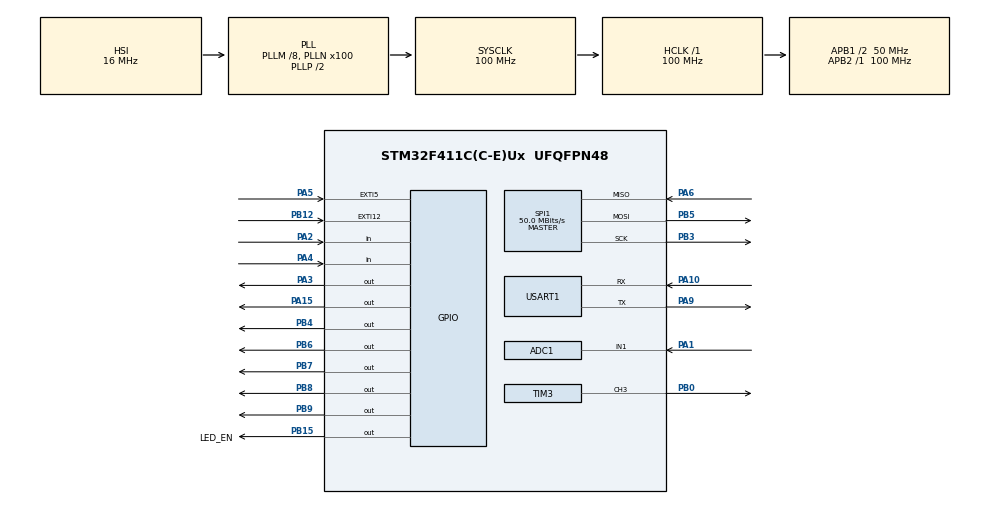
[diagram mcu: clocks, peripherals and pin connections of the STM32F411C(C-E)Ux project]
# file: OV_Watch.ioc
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ADC1.Channel-0\#ChannelRegularConversion=ADC_CHANNEL_1
ADC1.NbrOfConversionFlag=1
ADC1.Rank-0\#ChannelRegularConversion=1
ADC1.SamplingTime-0\#ChannelRegularConversion=ADC_SAMPLETIME_3CYCLES
ADC1.master=1
Dma.Request0=SPI1_TX
Dma.SPI1_TX.0.Direction=DMA_MEMORY_TO_PERIPH
Dma.SPI1_TX.0.FIFOMode=DMA_FIFOMODE_DISABLE
Dma.SPI1_TX.0.Instance=DMA2_Stream2
Dma.SPI1_TX.0.MemDataAlignment=DMA_MDATAALIGN_BYTE
Dma.SPI1_TX.0.MemInc=DMA_MINC_ENABLE
Dma.SPI1_TX.0.Mode=DMA_NORMAL
Dma.SPI1_TX.0.PeriphDataAlignment=DMA_PDATAALIGN_BYTE
Dma.SPI1_TX.0.PeriphInc=DMA_PINC_DISABLE
Dma.SPI1_TX.0.Priority=DMA_PRIORITY_HIGH
Mcu.Family=STM32F4
Mcu.Name=STM32F411C(C-E)Ux
Mcu.Package=UFQFPN48
NVIC.DMA2_Stream2_IRQn=true\:0\:0\:false\:false\:true\:false\:true\:true
NVIC.EXTI15_10_IRQn=true\:0\:0\:false\:false\:true\:true\:true\:true
NVIC.EXTI9_5_IRQn=true\:0\:0\:false\:false\:true\:true\:true\:true
NVIC.PriorityGroup=NVIC_PRIORITYGROUP_4
NVIC.SPI1_IRQn=true\:0\:0\:false\:false\:true\:true\:true\:true
NVIC.TIM1_UP_TIM10_IRQn=true\:0\:0\:false\:false\:true\:true\:true\:true
NVIC.USART1_IRQn=true\:0\:0\:false\:false\:true\:true\:true\:true
PA1.Signal=SharedAnalog_PA1
PA10.Mode=Asynchronous
PA10.Signal=USART1_RX
PA13.Mode=Serial_Wire
PA13.Signal=SYS_JTMS-SWDIO
PA14.Mode=Serial_Wire
PA14.Signal=SYS_JTCK-SWCLK
PA15.GPIO_PuPd=GPIO_PULLUP
PA15.PinState=GPIO_PIN_SET
PA15.Signal=GPIO_Output
PA2.GPIO_PuPd=GPIO_PULLUP
PA2.Signal=GPIO_Input
PA3.PinState=GPIO_PIN_SET
PA3.Signal=GPIO_Output
PA4.GPIO_PuPd=GPIO_PULLDOWN
PA4.Signal=GPIO_Input
PA5.GPIO_ModeDefaultEXTI=GPIO_MODE_IT_FALLING
PA5.GPIO_PuPd=GPIO_PULLUP
PA5.Signal=GPXTI5
PA6.Mode=Full_Duplex_Master
PA6.Signal=SPI1_MISO
PA9.Mode=Asynchronous
PA9.Signal=USART1_TX
PB0.Signal=S_TIM3_CH3
PB12.GPIO_ModeDefaultEXTI=GPIO_MODE_IT_FALLING
PB12.GPIO_PuPd=GPIO_PULLUP
PB12.Signal=GPXTI12
PB15.GPIO_Label=LED_EN
PB15.GPIO_PuPd=GPIO_NOPULL
PB15.PinState=GPIO_PIN_SET
PB15.Signal=GPIO_Output
PB3.Mode=Full_Duplex_Master
PB3.Signal=SPI1_SCK
PB4.GPIO_ModeDefaultOutputPP=GPIO_MODE_OUTPUT_OD
PB4.GPIO_PuPd=GPIO_PULLUP
PB4.GPIO_Speed=GPIO_SPEED_FREQ_HIGH
PB4.PinState=GPIO_PIN_SET
PB4.Signal=GPIO_Output
PB5.Mode=Full_Duplex_Master
PB5.Signal=SPI1_MOSI
PB6.GPIO_ModeDefaultOutputPP=GPIO_MODE_OUTPUT_OD
PB6.GPIO_PuPd=GPIO_PULLUP
PB6.GPIO_Speed=GPIO_SPEED_FREQ_HIGH
PB6.PinState=GPIO_PIN_SET
PB6.Signal=GPIO_Output
PB7.GPIO_PuPd=GPIO_PULLUP
PB7.PinState=GPIO_PIN_SET
PB7.Signal=GPIO_Output
PB8.GPIO_PuPd=GPIO_PULLUP
PB8.GPIO_Speed=GPIO_SPEED_FREQ_HIGH
PB8.PinState=GPIO_PIN_SET
PB8.Signal=GPIO_Output
PB9.GPIO_PuPd=GPIO_NOPULL
PB9.GPIO_Speed=GPIO_SPEED_FREQ_HIGH
PB9.PinState=GPIO_PIN_SET
PB9.Signal=GPIO_Output
PC14-OSC32_IN.Mode=LSE-External-Oscillator
PC14-OSC32_IN.Signal=RCC_OSC32_IN
PC15-OSC32_OUT.Mode=LSE-External-Oscillator
PC15-OSC32_OUT.Signal=RCC_OSC32_OUT
ProjectManager.HeapSize=0x200
ProjectManager.StackSize=0x400
ProjectManager.TargetToolchain=CMake
RCC.48MHZClocksFreq_Value=50000000
RCC.AHBFreq_Value=100000000
RCC.APB1CLKDivider=RCC_HCLK_DIV2
RCC.APB1Freq_Value=50000000
RCC.APB1TimFreq_Value=100000000
RCC.APB2Freq_Value=100000000
RCC.APB2TimFreq_Value=100000000
RCC.CortexFreq_Value=100000000
RCC.HCLKFreq_Value=100000000
RCC.HSE_VALUE=25000000
RCC.HSI_VALUE=16000000
RCC.PLLM=8
RCC.PLLN=100
RCC.SYSCLKFreq_VALUE=100000000
RCC.SYSCLKSource=RCC_SYSCLKSOURCE_PLLCLK
RCC.VCOOutputFreq_Value=200000000
RTC.Date=15
RTC.Hours=12
RTC.Month=RTC_MONTH_JULY
RTC.Year=26
SH.S_TIM3_CH3.0=TIM3_CH3,PWM Generation3 CH3
SH.SharedAnalog_PA1.0=GPIO_Analog
SH.SharedAnalog_PA1.1=ADC1_IN1,IN1
SPI1.BaudRatePrescaler=SPI_BAUDRATEPRESCALER_2
SPI1.CalculateBaudRate=50.0 MBits/s
SPI1.DataSize=SPI_DATASIZE_8BIT
SPI1.Direction=SPI_DIRECTION_2LINES
SPI1.Mode=SPI_MODE_MASTER
SPI1.VirtualType=VM_MASTER
TIM10.Prescaler=99
TIM3.Channel-PWM\ Generation3\ CH3=TIM_CHANNEL_3
TIM3.CounterMode=TIM_COUNTERMODE_UP
TIM3.Period=999
TIM3.Prescaler=9
TIM3.Pulse-PWM\ Generation3\ CH3=800
USART1.VirtualMode=VM_ASYNC
VP_RTC_VS_RTC_Activate.Mode=RTC_Enabled
VP_RTC_VS_RTC_Calendar.Mode=RTC_Calendar
VP_TIM10_VS_ClockSourceINT.Mode=Enable_Timer
board=custom

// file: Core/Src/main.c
/* USER CODE BEGIN Header */
/**
  ******************************************************************************
  * @file           : main.c
  * @brief          : Main program body
  ******************************************************************************
  * @attention
  *
  * Copyright (c) 2026 STMicroelectronics.
  * All rights reserved.
  *
  * This software is licensed under terms that can be found in the LICENSE file
  * in the root directory of this software component.
  * If no LICENSE file comes with this software, it is provided AS-IS.
  *
  ******************************************************************************
  */
/* USER CODE END Header */
#include "main.h"
#include "adc.h"
#include "dma.h"
#include "rtc.h"
#include "spi.h"
#include "tim.h"
#include "usart.h"
#include "gpio.h"

/* USER CODE BEGIN Includes */
#include "lcd.h"
#include "app.h"
/* USER CODE END Includes */

void SystemClock_Config(void);

int main(void)
{

  /* MCU Configuration--------------------------------------------------------*/

  /* Reset of all peripherals, Initializes the Flash interface and the Systick. */
  HAL_Init();

  /* Configure the system clock */
  SystemClock_Config();

  /* Initialize all configured peripherals */
  MX_GPIO_Init();
  MX_DMA_Init();
  MX_ADC1_Init();
  MX_SPI1_Init();
  MX_TIM10_Init();
  MX_USART1_UART_Init();
  MX_TIM3_Init();
  MX_RTC_Init();
  /* USER CODE BEGIN 2 */

  App_Init();

  /* USER CODE END 2 */

  /* Infinite loop */
  /* USER CODE BEGIN WHILE */
  while (1)
  {
    App_Update();
    /* USER CODE END WHILE */

  }
}

void SystemClock_Config(void)
{
  RCC_OscInitTypeDef RCC_OscInitStruct = {0};
  RCC_ClkInitTypeDef RCC_ClkInitStruct = {0};

  /** Configure the main internal regulator output voltage
  */
  __HAL_RCC_PWR_CLK_ENABLE();
  __HAL_PWR_VOLTAGESCALING_CONFIG(PWR_REGULATOR_VOLTAGE_SCALE1);

  /** Initializes the RCC Oscillators according to the specified parameters
  * in the RCC_OscInitTypeDef structure.
  */
  RCC_OscInitStruct.OscillatorType = RCC_OSCILLATORTYPE_HSI|RCC_OSCILLATORTYPE_LSI;
  RCC_OscInitStruct.HSIState = RCC_HSI_ON;
  RCC_OscInitStruct.HSICalibrationValue = RCC_HSICALIBRATION_DEFAULT;
  RCC_OscInitStruct.LSIState = RCC_LSI_ON;
  RCC_OscInitStruct.PLL.PLLState = RCC_PLL_ON;
  RCC_OscInitStruct.PLL.PLLSource = RCC_PLLSOURCE_HSI;
  RCC_OscInitStruct.PLL.PLLM = 8;
  RCC_OscInitStruct.PLL.PLLN = 100;
  RCC_OscInitStruct.PLL.PLLP = RCC_PLLP_DIV2;
  RCC_OscInitStruct.PLL.PLLQ = 4;
  if (HAL_RCC_OscConfig(&RCC_OscInitStruct) != HAL_OK)
  {
    Error_Handler();
  }

  /** Initializes the CPU, AHB and APB buses clocks
  */
  RCC_ClkInitStruct.ClockType = RCC_CLOCKTYPE_HCLK|RCC_CLOCKTYPE_SYSCLK
                              |RCC_CLOCKTYPE_PCLK1|RCC_CLOCKTYPE_PCLK2;
  RCC_ClkInitStruct.SYSCLKSource = RCC_SYSCLKSOURCE_PLLCLK;
  RCC_ClkInitStruct.AHBCLKDivider = RCC_SYSCLK_DIV1;
  RCC_ClkInitStruct.APB1CLKDivider = RCC_HCLK_DIV2;
  RCC_ClkInitStruct.APB2CLKDivider = RCC_HCLK_DIV1;

  if (HAL_RCC_ClockConfig(&RCC_ClkInitStruct, FLASH_LATENCY_3) != HAL_OK)
  {
    Error_Handler();
  }
}

void Error_Handler(void)
{
  __disable_irq();
  while (1)
  {
  }
}
